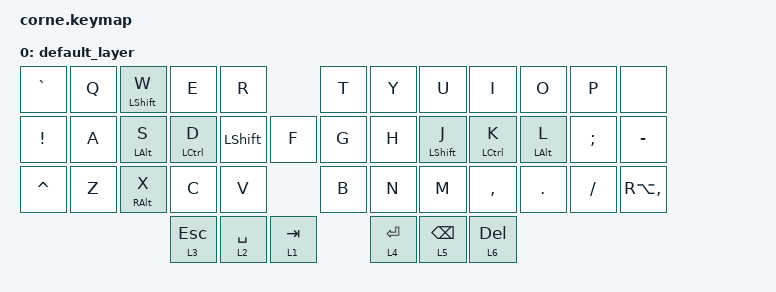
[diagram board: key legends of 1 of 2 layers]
/*
 * Copyright (c) 2020 The ZMK Contributors
 *
 * SPDX-License-Identifier: MIT
 */

#include <behaviors.dtsi>
#include <dt-bindings/zmk/keys.h>
#include <dt-bindings/zmk/bt.h>

/ {
        keymap {
                compatible = "zmk,keymap";

                default_layer {
                        bindings = <
   &kp GRAVE    &kp Q           &mt LSHFT W     &kp E           &kp R           &kp T           &kp Y           &kp U           &kp I           &kp O           &kp P           &none
   &kp EXCL     &kp A           &mt LALT S      &mt LCTRL D     &kp LSHFT F     &kp G           &kp H           &mt LSHFT J     &mt LCTRL K     &mt LALT L      &kp SEMI        &kp MINUS
   &kp CARET    &kp Z           &mt RALT X      &kp C           &kp V           &kp B           &kp N           &kp M           &kp COMMA       &kp DOT         &kp FSLH        &kp RA(COMMA)
                                                &lt 3 ESC     &lt 2 SPACE       &lt 1 TAB       &lt 4 RET       &lt 5 BSPC       &lt 6 DEL
                        >;
                };
                1 {
                        bindings = <
   &kp TAB    &kp N1       &kp N2       &kp N3       &kp N4       &kp N5         &kp N6   &kp N7   &kp N8 &kp N9    &kp N0 &kp BSPC
   &bt BT_CLR &bt BT_SEL 0 &bt BT_SEL 1 &bt BT_SEL 2 &bt BT_SEL 3 &bt BT_SEL 4   &kp LEFT &kp DOWN &kp UP &kp RIGHT &trans &trans
   &kp LSHFT  &trans       &trans       &trans       &trans       &trans         &trans   &trans   &trans &trans    &trans &trans
                                    &kp ESC          &kp SPACE          &kp TAB          &kp RET  &kp BSPC   &kp DEL
                        >;
                };

//                raise_layer {
//                        bindings = <
//   &kp  TAB  &kp EXCL &kp AT &kp HASH &kp DLLR &kp PRCNT   &kp CARET &kp AMPS  &kp ASTRK &kp LPAR &kp RPAR &kp BSPC
//   &kp LCTRL &trans   &trans &trans   &trans   &trans      &kp MINUS &kp EQUAL &kp LBKT  &kp RBKT &kp BSLH &kp GRAVE
//   &kp LSHFT &trans   &trans &trans   &trans   &trans      &kp UNDER &kp PLUS  &kp LBRC  &kp RBRC &kp PIPE &kp TILDE
//                             &kp LGUI &trans   &kp SPACE   &kp RET   &trans    &kp RALT
//                        >;
//                };
        };
};
